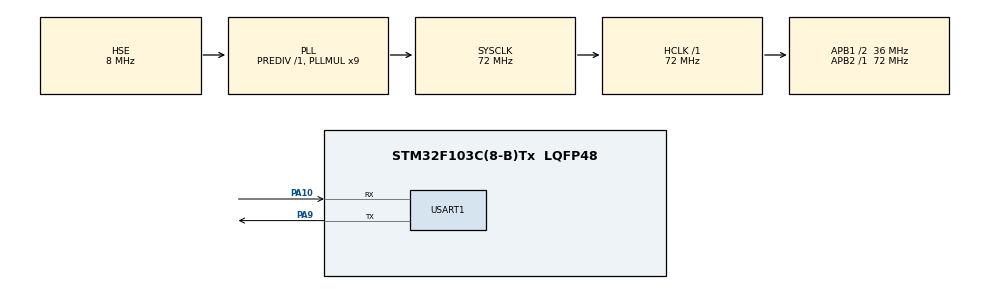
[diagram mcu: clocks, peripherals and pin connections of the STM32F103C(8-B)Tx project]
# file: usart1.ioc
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Dma.Request0=USART1_RX
Dma.USART1_RX.0.Direction=DMA_PERIPH_TO_MEMORY
Dma.USART1_RX.0.Instance=DMA1_Channel5
Dma.USART1_RX.0.MemDataAlignment=DMA_MDATAALIGN_BYTE
Dma.USART1_RX.0.MemInc=DMA_MINC_ENABLE
Dma.USART1_RX.0.Mode=DMA_NORMAL
Dma.USART1_RX.0.PeriphDataAlignment=DMA_PDATAALIGN_BYTE
Dma.USART1_RX.0.PeriphInc=DMA_PINC_DISABLE
Dma.USART1_RX.0.Priority=DMA_PRIORITY_LOW
FREERTOS.Tasks01=defaultTask,0,128,StartDefaultTask,Default,NULL
FREERTOS.configTOTAL_HEAP_SIZE=9216
Mcu.Family=STM32F1
Mcu.Name=STM32F103C(8-B)Tx
Mcu.Package=LQFP48
NVIC.DMA1_Channel5_IRQn=true\:5\:0\:false\:false\:true\:true\:false\:true
NVIC.PriorityGroup=NVIC_PRIORITYGROUP_4
NVIC.TIM2_IRQn=true\:0\:0\:false\:false\:true\:false\:false\:true
NVIC.TimeBase=TIM2_IRQn
NVIC.TimeBaseIP=TIM2
NVIC.USART1_IRQn=true\:5\:0\:false\:false\:true\:true\:true\:true
PA10.Mode=Asynchronous
PA10.Signal=USART1_RX
PA9.Mode=Asynchronous
PA9.Signal=USART1_TX
PD0-OSC_IN.Mode=HSE-External-Oscillator
PD0-OSC_IN.Signal=RCC_OSC_IN
PD1-OSC_OUT.Mode=HSE-External-Oscillator
PD1-OSC_OUT.Signal=RCC_OSC_OUT
ProjectManager.HeapSize=0x200
ProjectManager.StackSize=0x400
ProjectManager.TargetToolchain=MDK-ARM V5
RCC.AHBFreq_Value=72000000
RCC.APB1CLKDivider=RCC_HCLK_DIV2
RCC.APB1Freq_Value=36000000
RCC.APB1TimFreq_Value=72000000
RCC.APB2Freq_Value=72000000
RCC.APB2TimFreq_Value=72000000
RCC.HCLKFreq_Value=72000000
RCC.PLLMUL=RCC_PLL_MUL9
RCC.PLLSourceVirtual=RCC_PLLSOURCE_HSE
RCC.SYSCLKFreq_VALUE=72000000
RCC.SYSCLKSource=RCC_SYSCLKSOURCE_PLLCLK
RCC.USBFreq_Value=72000000
USART1.VirtualMode=VM_ASYNC
VP_FREERTOS_VS_CMSIS_V1.Mode=CMSIS_V1
VP_SYS_VS_ND.Mode=No_Debug
VP_SYS_VS_tim2.Mode=TIM2
board=custom

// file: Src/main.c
/* USER CODE BEGIN Header */
/**
  ******************************************************************************
  * @file           : main.c
  * @brief          : Main program body
  ******************************************************************************
  * @attention
  *
  * <h2><center>&copy; Copyright (c) 2020 STMicroelectronics.
  * All rights reserved.</center></h2>
  *
  * This software component is licensed by ST under Ultimate Liberty license
  * SLA0044, the "License"; You may not use this file except in compliance with
  * the License. You may obtain a copy of the License at:
  *                             www.st.com/SLA0044
  *
  ******************************************************************************
  */
/* USER CODE END Header */

#include "main.h"
#include "cmsis_os.h"
#include "dma.h"
#include "usart.h"
#include "gpio.h"

/* USER CODE BEGIN Includes */
#include <stdio.h>
/* USER CODE END Includes */

/* USER CODE BEGIN PV */
//UART_HandleTypeDef huart1;
//DMA_HandleTypeDef hdma_usart1_rx;

//osThreadId defaultTaskHandle;
//USART_RECEIVETYPE UsartType;

osPoolId pool_id;
osPoolDef(pool_t, 5, SUARTMsg);	//定义了10个大小为siziof(test_t)的内存池

osMessageQDef(q1,5,osPoolId);	//定义了最多接收5条消息的队列
osMessageQId q_id;
/* USER CODE END PV */

void SystemClock_Config(void);
void MX_FREERTOS_Init(void);

/* USER CODE BEGIN 0 */
//实现printf通过串口输出
int fputc(int ch, FILE *f)
{
	HAL_UART_Transmit(&huart1, (uint8_t *)&ch, 1, 0xFFFF);
	return ch;
}
/* USER CODE END 0 */

int main(void)
{

  /* MCU Configuration--------------------------------------------------------*/

  /* Reset of all peripherals, Initializes the Flash interface and the Systick. */
  HAL_Init();

  /* Configure the system clock */
  SystemClock_Config();

  /* USER CODE BEGIN SysInit */
	pool_id = osPoolCreate(osPool(pool_t));							//创建内存池
	q_id = osMessageCreate(osMessageQ(q1),NULL);				//创建队列
  /* USER CODE END SysInit */

  /* Initialize all configured peripherals */
  MX_GPIO_Init();
  MX_DMA_Init();
  MX_USART1_UART_Init();

  /* Call init function for freertos objects (in freertos.c) */
  MX_FREERTOS_Init();

  /* Start scheduler */
  osKernelStart();

  /* We should never get here as control is now taken by the scheduler */

  /* Infinite loop */
  while (1)
  {

  }
}

void SystemClock_Config(void)
{
  RCC_OscInitTypeDef RCC_OscInitStruct = {0};
  RCC_ClkInitTypeDef RCC_ClkInitStruct = {0};

  /** Initializes the CPU, AHB and APB busses clocks
  */
  RCC_OscInitStruct.OscillatorType = RCC_OSCILLATORTYPE_HSE;
  RCC_OscInitStruct.HSEState = RCC_HSE_ON;
  RCC_OscInitStruct.HSEPredivValue = RCC_HSE_PREDIV_DIV1;
  RCC_OscInitStruct.HSIState = RCC_HSI_ON;
  RCC_OscInitStruct.PLL.PLLState = RCC_PLL_ON;
  RCC_OscInitStruct.PLL.PLLSource = RCC_PLLSOURCE_HSE;
  RCC_OscInitStruct.PLL.PLLMUL = RCC_PLL_MUL9;
  if (HAL_RCC_OscConfig(&RCC_OscInitStruct) != HAL_OK)
  {
    Error_Handler();
  }
  /** Initializes the CPU, AHB and APB busses clocks
  */
  RCC_ClkInitStruct.ClockType = RCC_CLOCKTYPE_HCLK|RCC_CLOCKTYPE_SYSCLK
                              |RCC_CLOCKTYPE_PCLK1|RCC_CLOCKTYPE_PCLK2;
  RCC_ClkInitStruct.SYSCLKSource = RCC_SYSCLKSOURCE_PLLCLK;
  RCC_ClkInitStruct.AHBCLKDivider = RCC_SYSCLK_DIV1;
  RCC_ClkInitStruct.APB1CLKDivider = RCC_HCLK_DIV2;
  RCC_ClkInitStruct.APB2CLKDivider = RCC_HCLK_DIV1;

  if (HAL_RCC_ClockConfig(&RCC_ClkInitStruct, FLASH_LATENCY_2) != HAL_OK)
  {
    Error_Handler();
  }
}

void HAL_TIM_PeriodElapsedCallback(TIM_HandleTypeDef *htim)
{
  if (htim->Instance == TIM2) {
    HAL_IncTick();
  }
}

void Error_Handler(void)
{
}

/************************ (C) COPYRIGHT STMicroelectronics *****END OF FILE****/

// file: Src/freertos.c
/* USER CODE BEGIN Header */
/**
  ******************************************************************************
  * File Name          : freertos.c
  * Description        : Code for freertos applications
  ******************************************************************************
  * @attention
  *
  * <h2><center>&copy; Copyright (c) 2020 STMicroelectronics.
  * All rights reserved.</center></h2>
  *
  * This software component is licensed by ST under Ultimate Liberty license
  * SLA0044, the "License"; You may not use this file except in compliance with
  * the License. You may obtain a copy of the License at:
  *                             www.st.com/SLA0044
  *
  ******************************************************************************
  */
/* USER CODE END Header */

#include "FreeRTOS.h"
#include "task.h"
#include "main.h"
#include "cmsis_os.h"

/* USER CODE BEGIN Includes */
#include <stdio.h>
/* USER CODE END Includes */

/* USER CODE BEGIN PD */
void MsgTask(void const * argument);
/* USER CODE END PD */

/* USER CODE BEGIN Variables */
extern osMessageQId q_id;		//��Ϣ����
extern osPoolId pool_id;		//�ڴ��
/* USER CODE END Variables */
osThreadId defaultTaskHandle;

void StartDefaultTask(void const * argument);

void MX_FREERTOS_Init(void); /* (MISRA C 2004 rule 8.1) */

void MX_FREERTOS_Init(void) {

  /* Create the thread(s) */
  /* definition and creation of defaultTask */
  osThreadDef(defaultTask, StartDefaultTask, osPriorityNormal, 0, 128);
  defaultTaskHandle = osThreadCreate(osThread(defaultTask), NULL);

}

void StartDefaultTask(void const * argument)
{

  /* USER CODE BEGIN StartDefaultTask */
	osThreadDef(msgTask, MsgTask, osPriorityNormal, 0, 128);
  osThreadId msgTaskHandle = osThreadCreate(osThread(msgTask), NULL);

  /* Infinite loop */
	unsigned long i = 0;
  for(;;)
  {
		printf("running time[%lu]\r\n", ++i);
		if (NULL == msgTaskHandle)
		{
			printf("create thread failed.");
		}
    osDelay(1000);
  }
  /* USER CODE END StartDefaultTask */
}

/* USER CODE BEGIN Application */
void MsgTask(void const * argument)
{
	SUARTMsg* pMsg = NULL;
	osEvent stuEvent;
	while(1)
	{
		stuEvent = osMessageGet(q_id, osWaitForever);		//��ȡ��Ϣ
		if(stuEvent.status == osEventMessage)
		{
			pMsg = (SUARTMsg*)stuEvent.value.p;
			if (NULL != pMsg)
			{
				pMsg->m_arrMsg[LEN_MSG]=0;
				printf("recv: %s\r\nlen:[%d]\r\n", pMsg->m_arrMsg, pMsg->m_iLen);
				osPoolFree(pool_id, pMsg);
			}
			else
			{
				printf("WTF: pMsg is NULL.\r\n");
			}
		}
	}
}
/* USER CODE END Application */

/************************ (C) COPYRIGHT STMicroelectronics *****END OF FILE****/
